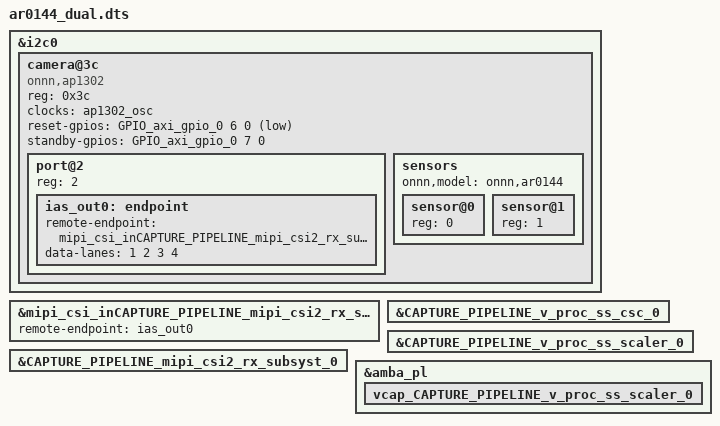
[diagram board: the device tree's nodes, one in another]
/dts-v1/;
/plugin/;

#include <dt-bindings/gpio/gpio.h>

/{
	fragment@0 {
		target = <&i2c0>;
		__overlay__ {
			camera@3c {
				status = "okay";
				compatible = "onnn,ap1302";
				reg = <0x3c>;

				clocks = <&ap1302_osc>;

				reset-gpios = <&GPIO_axi_gpio_0 6  0 GPIO_ACTIVE_LOW>;
				standby-gpios = <&GPIO_axi_gpio_0 7 0 GPIO_ACTIVE_HIGH>;

				port@2 {
					reg = <2>;
					ias_out0: endpoint {
						remote-endpoint = <&mipi_csi_inCAPTURE_PIPELINE_mipi_csi2_rx_subsyst_0>;
						data-lanes = <1 2 3 4>;
					};
				};

				sensors {
					#address-cells = <1>;
					#size-cells = <0>;

					onnn,model = "onnn,ar0144";

					sensor@0 {
						reg = <0>;
					};

					sensor@1 {
						reg = <1>;
					};
				};
			};
		};
	};

	fragment@1 {
		target = <&mipi_csi_inCAPTURE_PIPELINE_mipi_csi2_rx_subsyst_0>;
		__overlay__ {
			remote-endpoint = <&ias_out0>;
		};
	};

	fragment@2 {
		target = <&CAPTURE_PIPELINE_mipi_csi2_rx_subsyst_0>;
		__overlay__ {
			status = "okay";
		};
	};

	fragment@3 {
		target = <&CAPTURE_PIPELINE_v_proc_ss_csc_0>;
		__overlay__ {
			status = "okay";
		};
	};

	fragment@4 {
		target = <&CAPTURE_PIPELINE_v_proc_ss_scaler_0>;
		__overlay__ {
			status = "okay";
		};
	};

	fragment@5 {
		target = <&amba_pl>;
		__overlay__ {
			vcap_CAPTURE_PIPELINE_v_proc_ss_scaler_0 {
				status = "okay";
			};
		};
	};
};

